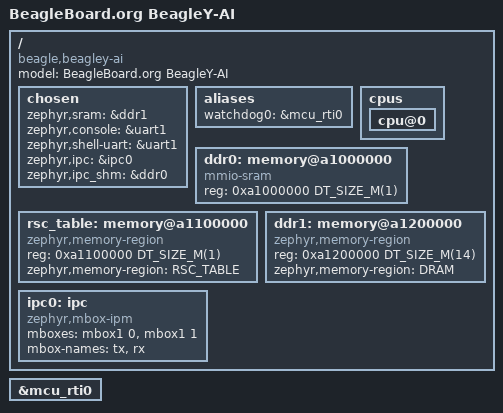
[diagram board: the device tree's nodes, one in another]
/*
 * Copyright (c) 2024 Texas Instruments Incorporated
 *	Andrew Davis <afd@ti.com>
 *
 * SPDX-License-Identifier: Apache-2.0
 */

/dts-v1/;

#include <ti/j722s_mcu_r5.dtsi>
#include "beagley_ai-common.dtsi"
#include <freq.h>

/ {
	model = "BeagleBoard.org BeagleY-AI";
	compatible = "beagle,beagley-ai";

	chosen {
		zephyr,sram = &ddr1;
		zephyr,console = &uart1;
		zephyr,shell-uart = &uart1;
		zephyr,ipc = &ipc0;
		zephyr,ipc_shm = &ddr0;
	};

	aliases {
		watchdog0 = &mcu_rti0;
	};

	cpus {
		cpu@0 {
			status = "okay";
		};
	};

	ddr0: memory@a1000000 {
		compatible = "mmio-sram";
		reg = <0xa1000000 DT_SIZE_M(1)>;
	};

	rsc_table: memory@a1100000 {
		compatible = "zephyr,memory-region", "mmio-sram";
		reg = <0xa1100000 DT_SIZE_M(1)>;
		zephyr,memory-region = "RSC_TABLE";
	};

	ddr1: memory@a1200000 {
		compatible = "zephyr,memory-region", "mmio-sram";
		reg = <0xa1200000 DT_SIZE_M(14)>;
		zephyr,memory-region = "DRAM";
	};

	ipc0: ipc {
		compatible = "zephyr,mbox-ipm";
		mboxes = <&mbox1 0>, <&mbox1 1>;
		mbox-names = "tx", "rx";
	};
};

&mcu_rti0 {
	status = "okay";
};
